# MDR1923VK014 register map
Vendor: Milandr; Series: ARMCM0; File version: 2.0
CPU: CM0 r0p0, little endian, no MPU, no FPU, 3 interrupt priority bits
Registers are 32-bit, read-write, reset 0x0 unless marked. A register's access mark holds for its fields unless they carry their own. Offsets are from the block's base; [hi:lo] are bit positions; {n}, {i} and the like mark numbered series; 'fields as' and 'values as' point back to an identical list.

## MDR_RST_CLOCK — CLock Control
Base 0x40000000
0x00 KEY — Clock Unlock Register
  [31:0] Value — Reg value
0x04 MAX_CLK — MAX_CLK Select Register
  [3:0] Select — Select MAX_CLOCK source
    0=HSI (MAX_CLOCK is HSI); 1=HSI_div2 (MAX_CLOCK is HSI/2); 2=HSE0 (MAX_CLOCK is HSE0); 3=HSE0_div2 (MAX_CLOCK is HSE0/2); 4=HSE1 (MAX_CLOCK is HSE1); 5=HSE1_div2 (MAX_CLOCK is HSE1/2); 6=LSI (MAX_CLOCK is LSI); 7=LSE (MAX_CLOCK is LSE); {v}=PLL{v-8} (MAX_CLOCK is PLL{v-8}) (v=8..15)
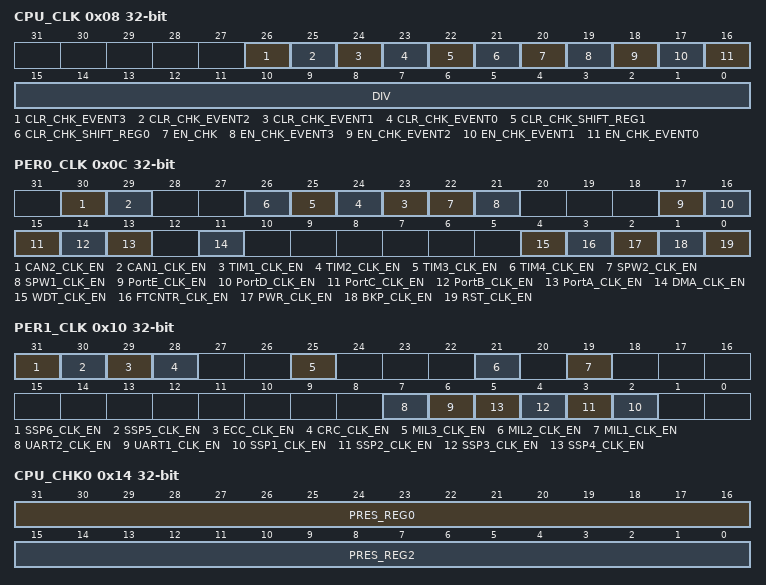
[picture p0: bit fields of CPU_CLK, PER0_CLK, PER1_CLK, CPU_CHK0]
0x08 CPU_CLK
  [26] CLR_CHK_EVENT3 — Clear highest freq event
    0=Inactive (No action); 1=Clear level
  [25] CLR_CHK_EVENT2 — Clear high freq event
    0=Inactive (No action); 1=Clear level
  [24] CLR_CHK_EVENT1 — Clear low freq event
    0=Inactive (No action); 1=Clear level
  [23] CLR_CHK_EVENT0 — Clear no freq event
    0=Inactive (No action); 1=Clear level
  [22] CLR_CHK_SHIFT_REG1 — Clear Max Freq level
    0=Inactive (No action); 1=Clear level
  [21] CLR_CHK_SHIFT_REG0 — Clear Min Freq level
    0=Inactive (No action); 1=Clear level
  [20] EN_CHK — Clock Checker enable
    0=Off (Disable); 1=On (Enable)
  [19] EN_CHK_EVENT3 — Go to HSI if active clock is Highest
    0=Off (Disable); 1=On (Enable)
  [18] EN_CHK_EVENT2 — Go to HSI if active clock is High
    0=Off (Disable); 1=On (Enable)
  [17] EN_CHK_EVENT1 — Go to HSI if active clock is low
    0=Off (Disable); 1=On (Enable)
  [16] EN_CHK_EVENT0 — Go to HSI on lose active clock
    0=Off (Disable); 1=On (Enable)
  [15:0] DIV — CPU_CLock div from MAX_CLOCK
0x0C PER0_CLK — Periph0 Clock Enable Register
  [all] fields
    0=Off (Disable); 1=On (Enable)
  [30] CAN2_CLK_EN — CAN2 Clock Enable
  [29] CAN1_CLK_EN — CAN1 Clock Enable
  [n+22] TIM{n}_CLK_EN (n=1..4) — TIM{n} Clock Enable
  [22] SPW2_CLK_EN — SPW2 Clock Enable
  [21] SPW1_CLK_EN — SPW1 Clock Enable
  [17] PortE_CLK_EN — GPIO Port Clock Enable
  [16] PortD_CLK_EN — GPIO Port Clock Enable
  [15] PortC_CLK_EN — GPIO Port Clock Enable
  [14] PortB_CLK_EN — GPIO Port Clock Enable
  [13] PortA_CLK_EN — GPIO Port Clock Enable
  [11] DMA_CLK_EN — DMA Clock Enable
  [4] WDT_CLK_EN — WDT Clock Enable
  [3] FTCNTR_CLK_EN — FT_CNTR Clock Enable
  [2] PWR_CLK_EN — Power Clock Enable
  [1] BKP_CLK_EN — BKP Clock Enable
  [0] RST_CLK_EN — RST Clock Enable
0x10 PER1_CLK (reset mask 0xF42800FC) — Periph1 Clock Enable Register
  [all] fields
    0=Off (Disable); 1=On (Enable)
  [31] SSP6_CLK_EN — SSP6 Clock Enable
  [30] SSP5_CLK_EN — SSP5 Clock Enable
  [29] ECC_CLK_EN — ECC Clock Enable
  [28] CRC_CLK_EN — CRC Clock Enable
  [25] MIL3_CLK_EN — MIL3 Clock Enable
  [21] MIL2_CLK_EN — MIL2 Clock Enable
  [19] MIL1_CLK_EN — MIL1 Clock Enable
  [7] UART2_CLK_EN — UART2 Clock Enable
  [6] UART1_CLK_EN — UART1 Clock Enable
  [n+1] SSP{n}_CLK_EN (n=1..4) — SSP{n} Clock Enable
0x14 CPU_CHK0 — Clock Checker Register
  [31:16] PRES_REG0 — FreqRef Prescaller for Fast
  [15:0] PRES_REG2 — FreqRef Prescaller for Slow
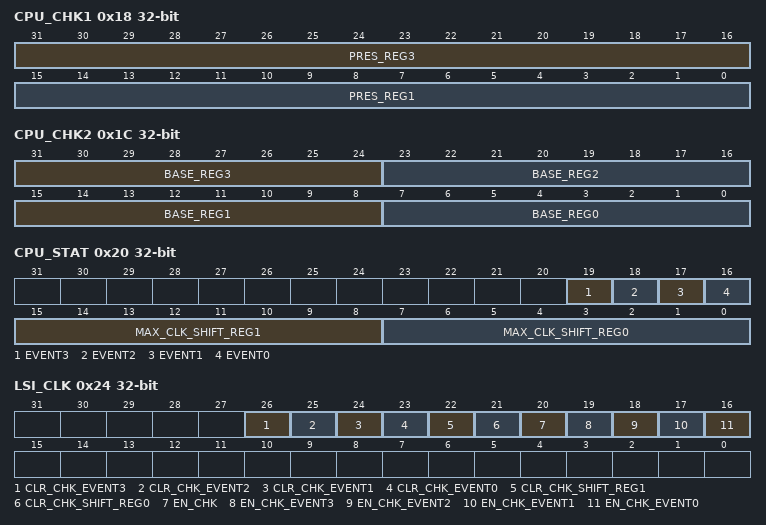
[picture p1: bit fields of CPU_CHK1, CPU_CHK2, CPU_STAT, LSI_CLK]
0x18 CPU_CHK1 — Clock Checker Register
  [31:16] PRES_REG3 — Clock Prescaller for Slow
  [15:0] PRES_REG1 — Clock Prescaller for Fast
0x1C CPU_CHK2 — Clock Checker Register
  [31:24] BASE_REG3 — Max factor for FASTEST
  [23:16] BASE_REG2 — Max factor for FAST
  [15:8] BASE_REG1 — Min factor for SLOW
  [7:0] BASE_REG0 — Min factor for SLOWEST
0x20 CPU_STAT — Clock Status Register
  [19] EVENT3 — Event FASTEST
    0=Off (Inactive); 1=On (Active)
  [18] EVENT2 — Event FAST
    0=Off (Inactive); 1=On (Active)
  [17] EVENT1 — Event SLOW
    0=Off (Inactive); 1=On (Active)
  [16] EVENT0 — Event SLOWEST
    0=Off (Inactive); 1=On (Active)
  [15:8] MAX_CLK_SHIFT_REG1 — Max factor detected for FAST
  [7:0] MAX_CLK_SHIFT_REG0 — Max factor detected for SLOW
0x24 LSI_CLK — Clock Contorl Register
  [26] CLR_CHK_EVENT3 — Clear highest freq event
    0=Inactive (No action); 1=Clear level
  [25] CLR_CHK_EVENT2 — Clear high freq event
    0=Inactive (No action); 1=Clear level
  [24] CLR_CHK_EVENT1 — Clear low freq event
    0=Inactive (No action); 1=Clear level
  [23] CLR_CHK_EVENT0 — Clear no freq event
    0=Inactive (No action); 1=Clear level
  [22] CLR_CHK_SHIFT_REG1 — Clear Max Freq level
    0=Inactive (No action); 1=Clear level
  [21] CLR_CHK_SHIFT_REG0 — Clear Min Freq level
    0=Inactive (No action); 1=Clear level
  [20] EN_CHK — Clock Checker enable
    0=Off (Disable); 1=On (Enable)
  [19] EN_CHK_EVENT3 — Go to HSI if active clock is Highest
    0=Off (Disable); 1=On (Enable)
  [18] EN_CHK_EVENT2 — Go to HSI if active clock is High
    0=Off (Disable); 1=On (Enable)
  [17] EN_CHK_EVENT1 — Go to HSI if active clock is low
    0=Off (Disable); 1=On (Enable)
  [16] EN_CHK_EVENT0 — Go to HSI on lose active clock
    0=Off (Disable); 1=On (Enable)
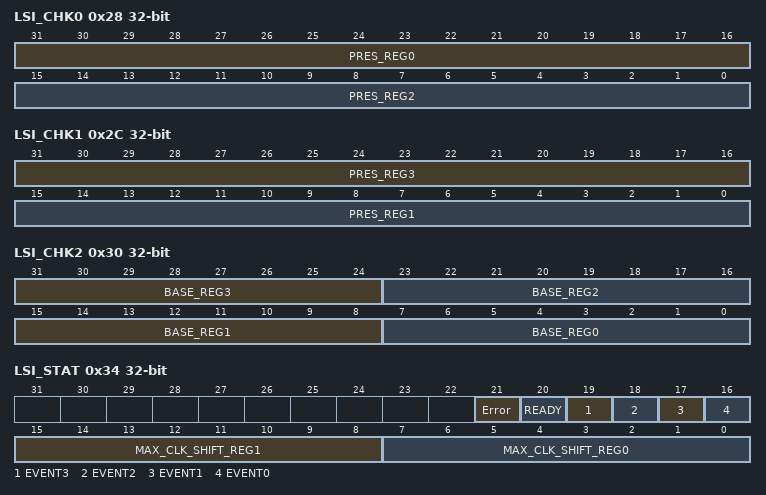
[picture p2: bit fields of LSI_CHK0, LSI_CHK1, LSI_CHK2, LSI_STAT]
0x28 LSI_CHK0 — Clock Checker Register
  fields as CPU_CHK0
0x2C LSI_CHK1 — Clock Checker Register
  fields as CPU_CHK1
0x30 LSI_CHK2 — Clock Checker Register
  fields as CPU_CHK2
0x34 LSI_STAT (reset mask 0xFFFFF) — Clock Status Register
  [21] Error — Clock Ready Error
    0=Off (Inactive state); 1=On (Ready Fault)
  [20] READY — Clock Ready
    0=Off (Clock not Ready); 1=On (Clock Ready)
  [19] EVENT3 — Event FASTEST
    0=Off (Inactive); 1=On (Active)
  [18] EVENT2 — Event FAST
    0=Off (Inactive); 1=On (Active)
  [17] EVENT1 — Event SLOW
    0=Off (Inactive); 1=On (Active)
  [16] EVENT0 — Event SLOWEST
    0=Off (Inactive); 1=On (Active)
  [15:8] MAX_CLK_SHIFT_REG1 — Max factor detected for FAST
  [7:0] MAX_CLK_SHIFT_REG0 — Max factor detected for SLOW
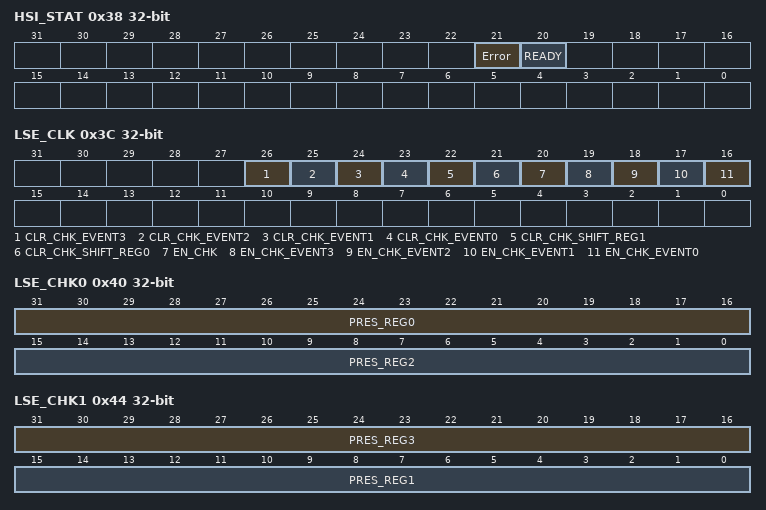
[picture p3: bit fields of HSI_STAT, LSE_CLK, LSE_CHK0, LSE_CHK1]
0x38 HSI_STAT (reset mask 0x100000) — HSI Status Register
  [21] Error — Clock Ready Error
    0=Off (Inactive state); 1=On (Ready Fault)
  [20] READY — Clock Ready
    0=Off (Clock not Ready); 1=On (Clock Ready)
0x3C LSE_CLK — Clock Contorl Register
  fields as LSI_CLK
0x40 LSE_CHK0 — Clock Checker Register
  fields as CPU_CHK0
0x44 LSE_CHK1 — Clock Checker Register
  fields as CPU_CHK1
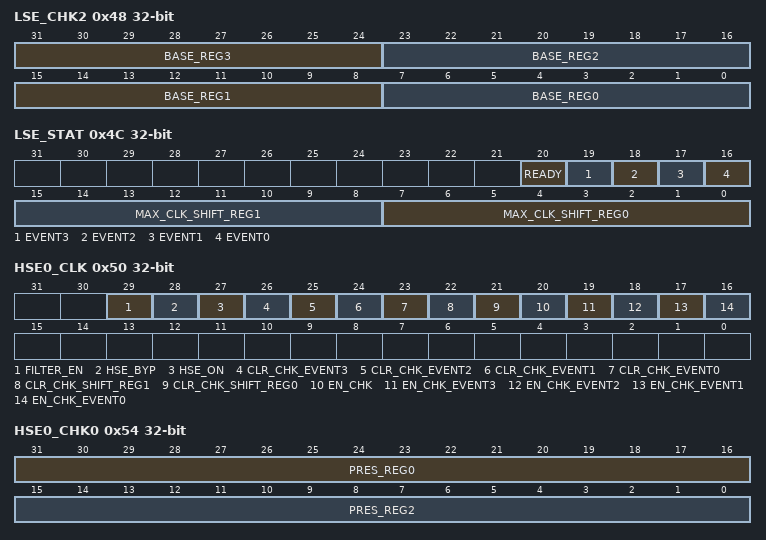
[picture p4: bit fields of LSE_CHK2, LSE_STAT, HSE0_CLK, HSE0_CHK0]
0x48 LSE_CHK2 — Clock Checker Register
  fields as CPU_CHK2
0x4C LSE_STAT (reset mask 0xFFFFF) — Clock Status Register
  [20] READY — Clock Ready
    0=Off (Clock not Ready); 1=On (Clock Ready)
  [19] EVENT3 — Event FASTEST
    0=Off (Inactive); 1=On (Active)
  [18] EVENT2 — Event FAST
    0=Off (Inactive); 1=On (Active)
  [17] EVENT1 — Event SLOW
    0=Off (Inactive); 1=On (Active)
  [16] EVENT0 — Event SLOWEST
    0=Off (Inactive); 1=On (Active)
  [15:8] MAX_CLK_SHIFT_REG1 — Max factor detected for FAST
  [7:0] MAX_CLK_SHIFT_REG0 — Max factor detected for SLOW
0x50 HSE0_CLK (reset mask 0x7FF0000) — Clock Contorl Register
  [29] FILTER_EN — Filter Enable
    0=Off (Disable); 1=On (Enable)
  [28] HSE_BYP — ByPass Mode
    0=Off (Disable); 1=On (Enable)
  [27] HSE_ON — Generator Enable
    0=Off (Disable); 1=On (Enable)
  [26] CLR_CHK_EVENT3 — Clear highest freq event
    0=Inactive (No action); 1=Clear level
  [25] CLR_CHK_EVENT2 — Clear high freq event
    0=Inactive (No action); 1=Clear level
  [24] CLR_CHK_EVENT1 — Clear low freq event
    0=Inactive (No action); 1=Clear level
  [23] CLR_CHK_EVENT0 — Clear no freq event
    0=Inactive (No action); 1=Clear level
  [22] CLR_CHK_SHIFT_REG1 — Clear Max Freq level
    0=Inactive (No action); 1=Clear level
  [21] CLR_CHK_SHIFT_REG0 — Clear Min Freq level
    0=Inactive (No action); 1=Clear level
  [20] EN_CHK — Clock Checker enable
    0=Off (Disable); 1=On (Enable)
  [19] EN_CHK_EVENT3 — Go to HSI if active clock is Highest
    0=Off (Disable); 1=On (Enable)
  [18] EN_CHK_EVENT2 — Go to HSI if active clock is High
    0=Off (Disable); 1=On (Enable)
  [17] EN_CHK_EVENT1 — Go to HSI if active clock is low
    0=Off (Disable); 1=On (Enable)
  [16] EN_CHK_EVENT0 — Go to HSI on lose active clock
    0=Off (Disable); 1=On (Enable)
0x54 HSE0_CHK0 — Clock Checker Register
  fields as CPU_CHK0
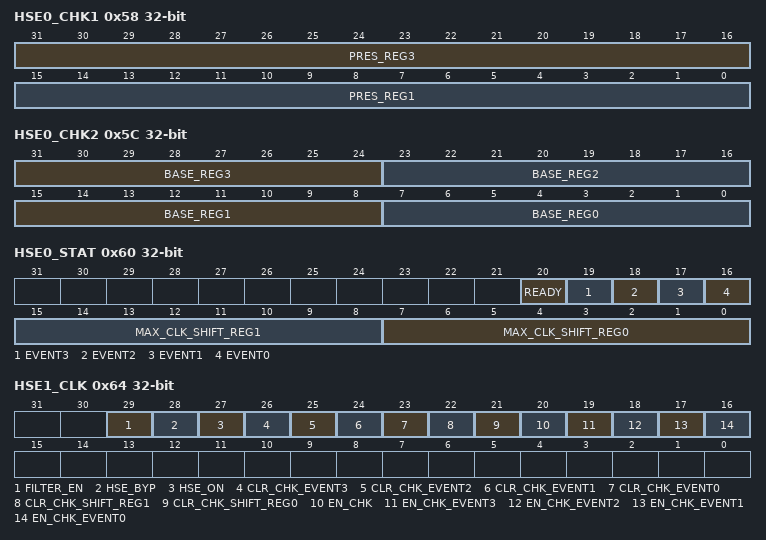
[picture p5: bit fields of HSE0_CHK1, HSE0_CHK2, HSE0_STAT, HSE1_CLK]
0x58 HSE0_CHK1 — Clock Checker Register
  fields as CPU_CHK1
0x5C HSE0_CHK2 — Clock Checker Register
  fields as CPU_CHK2
0x60 HSE0_STAT (reset mask 0xFFFFF) — Clock Status Register
  fields as LSE_STAT
0x64 HSE1_CLK (reset mask 0x7FF0000) — Clock Contorl Register
  fields as HSE0_CLK
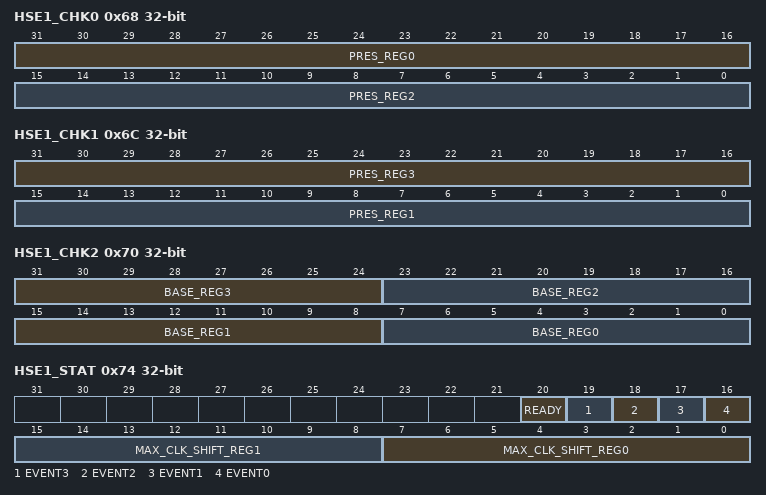
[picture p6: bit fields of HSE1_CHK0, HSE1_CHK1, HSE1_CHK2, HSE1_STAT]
0x68 HSE1_CHK0 — Clock Checker Register
  fields as CPU_CHK0
0x6C HSE1_CHK1 — Clock Checker Register
  fields as CPU_CHK1
0x70 HSE1_CHK2 — Clock Checker Register
  fields as CPU_CHK2
0x74 HSE1_STAT (reset mask 0xFFFFF) — Clock Status Register
  fields as LSE_STAT
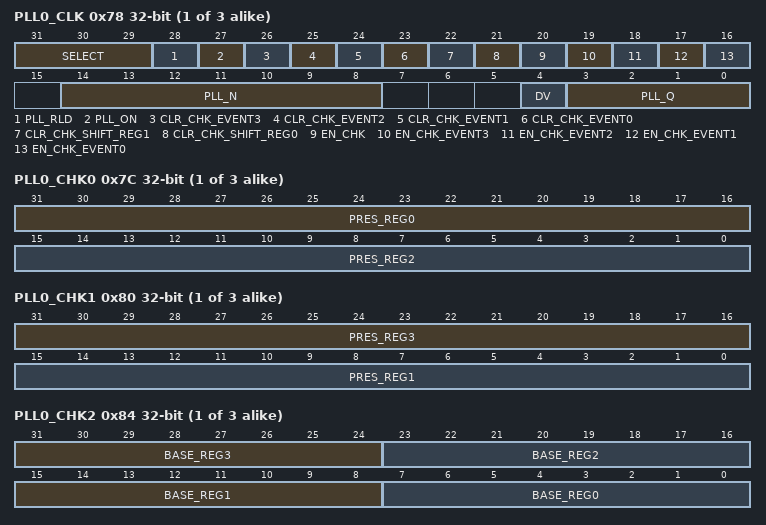
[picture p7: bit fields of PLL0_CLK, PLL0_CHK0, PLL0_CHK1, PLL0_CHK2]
{0x78+0x14*i} PLL{i}_CLK (i=0..2) — PLL0 Control
  [31:29] SELECT — Select PLL Input
    0=HSI (HSI signal); 1=HSI_div2 (HSI/2 signal); 2=HSE0 (HSE0 signal); 3=HSE0_div2 (HSE0/2 signal); 4=HSE1 (HSE1 signal); 5=HSE1_div2 (HSE1/2 signal)
  [28] PLL_RLD — PLL Reload
    0=Inactive state; 1=Reload PLL
  [27] PLL_ON — PLL Enable
    0=Off (Disable); 1=On (Enable)
  [26] CLR_CHK_EVENT3 — Clear highest freq event
    0=Inactive (No action); 1=Clear level
  [25] CLR_CHK_EVENT2 — Clear high freq event
    0=Inactive (No action); 1=Clear level
  [24] CLR_CHK_EVENT1 — Clear low freq event
    0=Inactive (No action); 1=Clear level
  [23] CLR_CHK_EVENT0 — Clear no freq event
    0=Inactive (No action); 1=Clear level
  [22] CLR_CHK_SHIFT_REG1 — Clear Max Freq level
    0=Inactive (No action); 1=Clear level
  [21] CLR_CHK_SHIFT_REG0 — Clear Min Freq level
    0=Inactive (No action); 1=Clear level
  [20] EN_CHK — Clock Checker enable
    0=Off (Disable); 1=On (Enable)
  [19] EN_CHK_EVENT3 — Go to HSI if active clock is Highest
    0=Off (Disable); 1=On (Enable)
  [18] EN_CHK_EVENT2 — Go to HSI if active clock is High
    0=Off (Disable); 1=On (Enable)
  [17] EN_CHK_EVENT1 — Go to HSI if active clock is low
    0=Off (Disable); 1=On (Enable)
  [16] EN_CHK_EVENT0 — Go to HSI on lose active clock
    0=Off (Disable); 1=On (Enable)
  [14:8] PLL_N — PLL Freq multiplier
  [4] DV — PLL Output Divider
    0=div1 (Divider); 1=div2 (Divider)
  [3:0] PLL_Q — PLL Freq divider
    {v}=div{v+1} (Divider) (v=0..15)
{0x7C+0x14*i} PLL{i}_CHK0 (i=0..2) — Clock Checker Register
  fields as CPU_CHK0
{0x80+0x14*i} PLL{i}_CHK1 (i=0..2) — Clock Checker Register
  fields as CPU_CHK1
{0x84+0x14*i} PLL{i}_CHK2 (i=0..2) — Clock Checker Register
  fields as CPU_CHK2
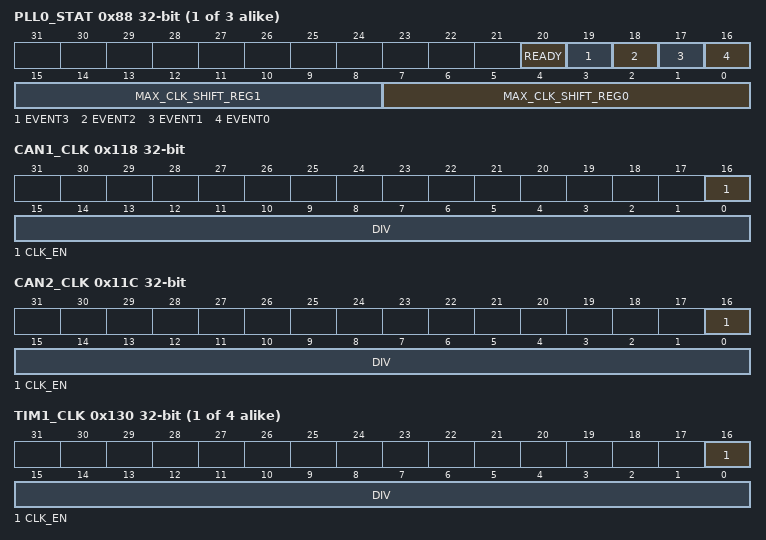
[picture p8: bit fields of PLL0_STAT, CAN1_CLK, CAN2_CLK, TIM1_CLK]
{0x88+0x14*i} PLL{i}_STAT (reset mask 0xFFFFF) (i=0..2) — Clock Status Register
  fields as LSE_STAT
0x118 CAN1_CLK (reset mask 0x1001FFF) — Sync Clock Control
  [16] CLK_EN — PeriphClock Enable
    0=Off (Clock Off); 1=On (Clock On)
  [15:0] DIV — MAX_Clock Div to PeriphClock
0x11C CAN2_CLK (reset mask 0x1001FFF) — Sync Clock Control
  fields as CAN1_CLK
{0x12C+4i} TIM{i}_CLK (reset mask 0x1001FFF) (i=1..4) — Sync Clock Control
  fields as CAN1_CLK
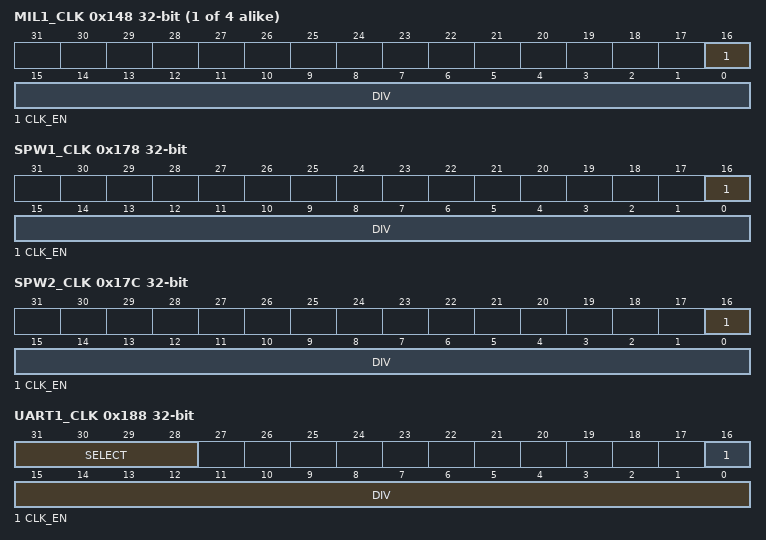
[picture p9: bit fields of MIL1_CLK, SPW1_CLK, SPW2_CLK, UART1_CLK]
{0x144+4i} MIL{i}_CLK (reset mask 0x1001FFF) (i=1..4) — Sync Clock Control
  fields as CAN1_CLK
0x178 SPW1_CLK (reset mask 0x1001FFF) — Sync Clock Control
  fields as CAN1_CLK
0x17C SPW2_CLK (reset mask 0x1001FFF) — Sync Clock Control
  fields as CAN1_CLK
0x188 UART1_CLK (reset mask 0xF001FFF) — Async Clock Control
  [31:28] SELECT — PeriphClock Enable
    0=HSI (Clock Source); 1=HSE0 (Clock Source); 2=HSE1 (Clock Source); 3=LSI (Clock Source); 4=LSE (Clock Source); 5=PLL0 (Clock Source); 6=PLL1 (Clock Source); 7=PLL2 (Clock Source); 13=MAX_CLK (Clock Source)
  [16] CLK_EN — PeriphClock Enable
    0=Off (Clock Off); 1=On (Clock On)
  [15:0] DIV — Div to PeriphClock
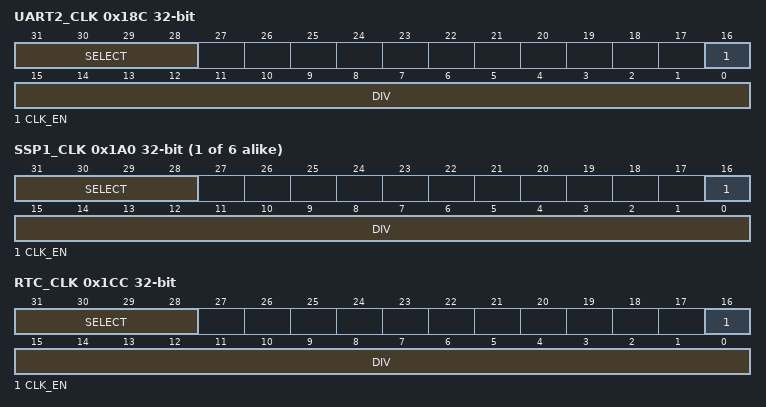
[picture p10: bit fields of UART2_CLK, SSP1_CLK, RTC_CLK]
0x18C UART2_CLK (reset mask 0xF001FFF) — Async Clock Control
  fields as UART1_CLK
{0x19C+4i} SSP{i}_CLK (reset mask 0xF001FFF) (i=1..6) — Async Clock Control
  fields as UART1_CLK
0x1CC RTC_CLK (reset mask 0xF001FFF) — Async Clock Control
  fields as UART1_CLK
